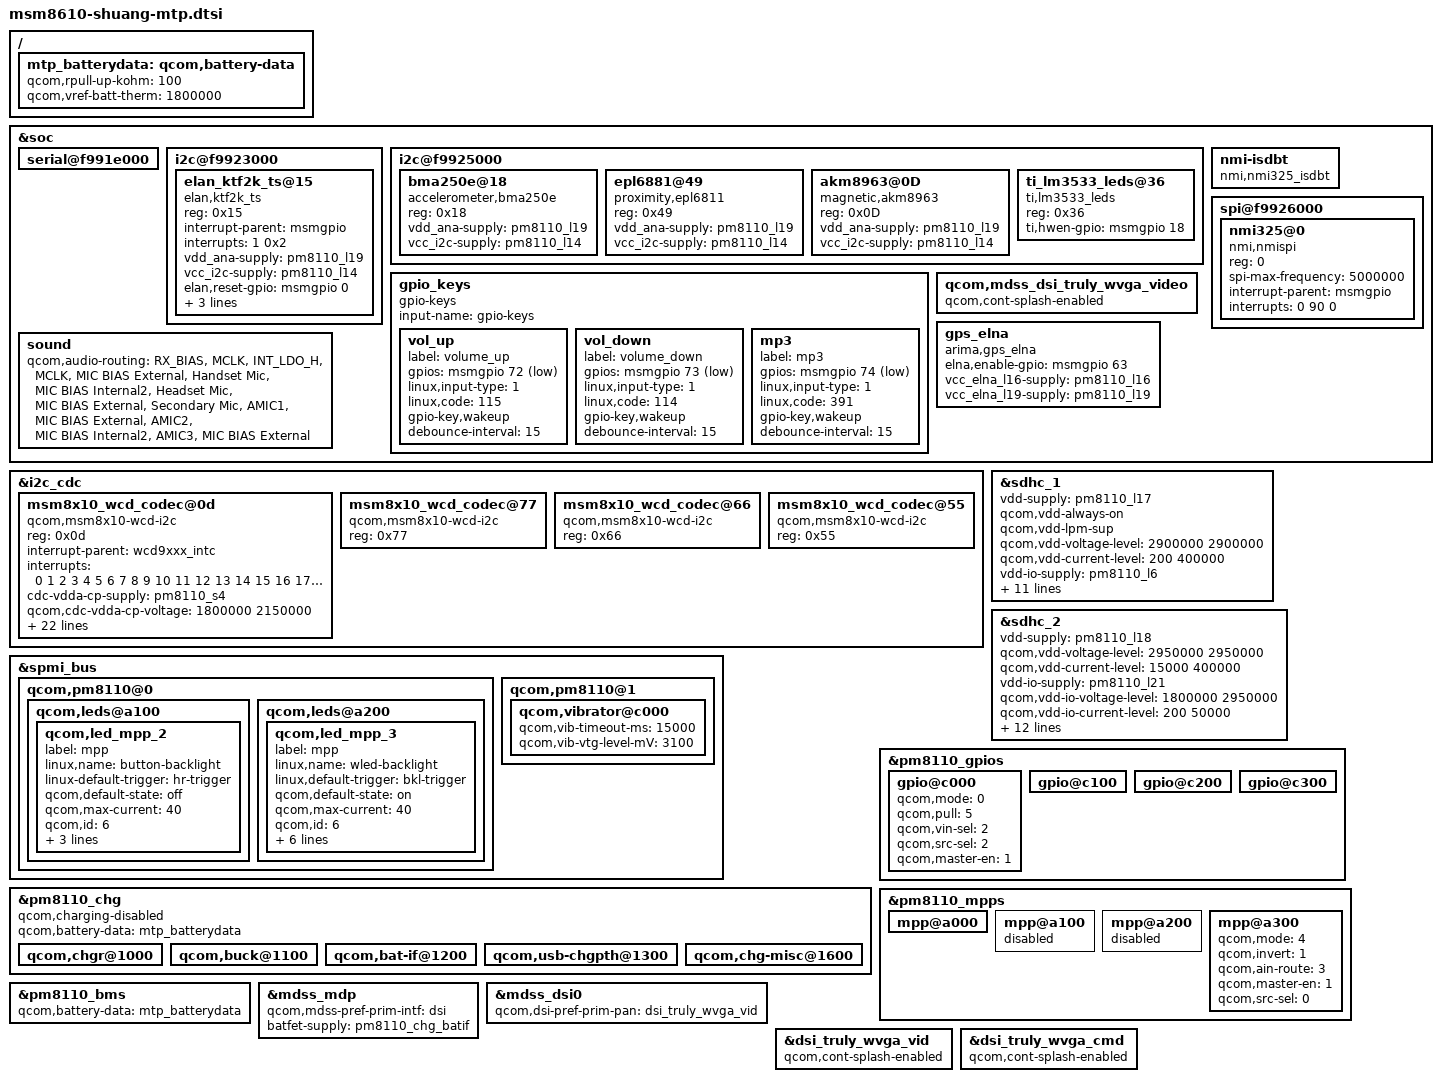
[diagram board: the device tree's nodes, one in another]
/* Copyright (c) 2013-2014, The Linux Foundation. All rights reserved.
 *
 * This program is free software; you can redistribute it and/or modify
 * it under the terms of the GNU General Public License version 2 and
 * only version 2 as published by the Free Software Foundation.
 *
 * This program is distributed in the hope that it will be useful,
 * but WITHOUT ANY WARRANTY; without even the implied warranty of
 * MERCHANTABILITY or FITNESS FOR A PARTICULAR PURPOSE.  See the
 * GNU General Public License for more details.
 */

&soc {
	serial@f991e000 {
		status = "ok";
	};

	i2c@f9923000 {
		elan_ktf2k_ts@15 {
			compatible = "elan,ktf2k_ts";
			reg = <0x15>;
			interrupt-parent = <&msmgpio>;
			interrupts = <1 0x2>;
			vdd_ana-supply = <&pm8110_l19>;
			vcc_i2c-supply = <&pm8110_l14>;
			elan,reset-gpio = <&msmgpio 0 0x00>;
			elan,irq-gpio = <&msmgpio 1 0x00>;
			elan,hw-det-gpio = <&msmgpio 7 0x00>;
			elan,i2c-pull-up;
		};
	};

	i2c@f9925000 {
		bma250e@18 {
			compatible = "accelerometer,bma250e";
			reg = <0x18>;
			vdd_ana-supply = <&pm8110_l19>;
			vcc_i2c-supply = <&pm8110_l14>;
		};
		epl6881@49 {
			compatible = "proximity,epl6811";
			reg = <0x49>;
			vdd_ana-supply = <&pm8110_l19>;
			vcc_i2c-supply = <&pm8110_l14>;
		};
		akm8963@0D {
			compatible = "magnetic,akm8963";
			reg = <0x0D>;
			vdd_ana-supply = <&pm8110_l19>;
			vcc_i2c-supply = <&pm8110_l14>;
		};
		ti_lm3533_leds@36 {
			compatible = "ti,lm3533_leds";
			reg = <0x36>;
			ti,hwen-gpio = <&msmgpio 18 0x00>;
		};
	};

	nmi-isdbt {
		compatible = "nmi,nmi325_isdbt";
	};

	spi@f9926000 {
		nmi325@0 {
			compatible = "nmi,nmispi";
			reg = <0>;
			spi-max-frequency = <5000000>;
			interrupt-parent = <&msmgpio>;
			interrupts = <0 90 0>;
		};
	};

	gpio_keys {
		compatible = "gpio-keys";
		input-name = "gpio-keys";

		vol_up {
			label = "volume_up";
			gpios = <&msmgpio 72 0x1>;
			linux,input-type = <1>;
			linux,code = <115>;
			gpio-key,wakeup;
			debounce-interval = <15>;
		};

		vol_down {
			label = "volume_down";
			gpios = <&msmgpio 73 0x1>;
			linux,input-type = <1>;
			linux,code = <114>;
			gpio-key,wakeup;
			debounce-interval = <15>;
		};

		mp3 {
			label = "mp3";
			gpios = <&msmgpio 74 0x1>;
			linux,input-type = <1>;
			linux,code = <391>;
			gpio-key,wakeup;
			debounce-interval = <15>;
		};
	};

    sound {
        qcom,audio-routing =
            "RX_BIAS", "MCLK",
            "INT_LDO_H", "MCLK",
            "MIC BIAS External", "Handset Mic",
            "MIC BIAS Internal2", "Headset Mic",
            "MIC BIAS External", "Secondary Mic",
            "AMIC1", "MIC BIAS External",
            "AMIC2", "MIC BIAS Internal2",
            "AMIC3", "MIC BIAS External";
    };

	qcom,mdss_dsi_truly_wvga_video {
		qcom,cont-splash-enabled;
	};

	gps_elna {
		compatible = "arima,gps_elna";
		elna,enable-gpio = <&msmgpio 63 0x00>;
		vcc_elna_l16-supply = <&pm8110_l16>;
		vcc_elna_l19-supply = <&pm8110_l19>;
	};
};

&i2c_cdc  {
	msm8x10_wcd_codec@0d{
		compatible = "qcom,msm8x10-wcd-i2c";
		reg = <0x0d>;

		interrupt-parent = <&wcd9xxx_intc>;
		interrupts = <0 1 2 3 4 5 6 7 8 9 10 11 12 13 14 15 16
			      17 18 19 20 21 22 23>;

		cdc-vdda-cp-supply = <&pm8110_s4>;
		qcom,cdc-vdda-cp-voltage = <1800000 2150000>;
		qcom,cdc-vdda-cp-current = <650000>;

		cdc-vdda-h-supply = <&pm8110_l6>;
		qcom,cdc-vdda-h-voltage = <1800000 1800000>;
		qcom,cdc-vdda-h-current = <25000>;

		cdc-vdd-px-supply = <&pm8110_l6>;
		qcom,cdc-vdd-px-voltage = <1800000 1800000>;
		qcom,cdc-vdd-px-current = <10000>;

		cdc-vdd-1p2v-supply = <&pm8110_l4>;
		qcom,cdc-vdd-1p2v-voltage = <1200000 1200000>;
		qcom,cdc-vdd-1p2v-current = <5000>;

		cdc-vdd-mic-bias-supply = <&pm8110_l20>;
		qcom,cdc-vdd-mic-bias-voltage = <3075000 3075000>;
		qcom,cdc-vdd-mic-bias-current = <25000>;

		qcom,cdc-micbias-ldoh-v = <0x3>;
		qcom,cdc-micbias-cfilt-sel = <0x0>;
		qcom,cdc-micbias-cfilt-mv = <2700>;
		qcom,cdc-mclk-clk-rate = <12288000>;

		qcom,cdc-static-supplies = "cdc-vdda-h",
					   "cdc-vdd-px",
					   "cdc-vdd-1p2v";

		qcom,cdc-on-demand-supplies = "cdc-vdda-cp",
					      "cdc-vdd-mic-bias";
		qcom,cdc-micbias1-ext-cap;
	};

	msm8x10_wcd_codec@77{
		compatible = "qcom,msm8x10-wcd-i2c";
		reg = <0x77>;
	};

	msm8x10_wcd_codec@66{
		compatible = "qcom,msm8x10-wcd-i2c";
		reg = <0x66>;
	};

	msm8x10_wcd_codec@55{
		compatible = "qcom,msm8x10-wcd-i2c";
		reg = <0x55>;
	};
};

&spmi_bus {
	qcom,pm8110@0 {
		qcom,leds@a100 {
			status = "okay";
			qcom,led_mpp_2 {
				label = "mpp";
				linux,name = "button-backlight";
				linux-default-trigger = "hr-trigger";
				qcom,default-state = "off";
				qcom,max-current = <40>;
				qcom,id = <6>;
				qcom,source-sel = <1>;
				qcom,mode-ctrl = <0x60>;
				qcom,mode = "manual";
			};
		};

		qcom,leds@a200 {
			status = "okay";
			qcom,led_mpp_3 {
				label = "mpp";
				linux,name = "wled-backlight";
				linux,default-trigger = "bkl-trigger";
				qcom,default-state = "on";
				qcom,max-current = <40>;
				qcom,id = <6>;
				qcom,source-sel = <8>;
				qcom,mode-ctrl = <0x10>;
				qcom,pwm-channel = <0>;
				qcom,pwm-us = <27>;
				qcom,vin-ctrl = <0x03>;
				qcom,mode = "pwm";
			};
		};
	};
};

&spmi_bus {
	qcom,pm8110@1 {
		qcom,vibrator@c000 {
			status = "okay";
			qcom,vib-timeout-ms = <15000>;
			qcom,vib-vtg-level-mV = <3100>;
		};
	};
};

&sdhc_1 {
	vdd-supply = <&pm8110_l17>;
	qcom,vdd-always-on;
	qcom,vdd-lpm-sup;
	qcom,vdd-voltage-level = <2900000 2900000>;
	qcom,vdd-current-level = <200 400000>;

	vdd-io-supply = <&pm8110_l6>;
	qcom,vdd-io-always-on;
	qcom,vdd-io-voltage-level = <1800000 1800000>;
	qcom,vdd-io-current-level = <200 60000>;

	qcom,pad-pull-on = <0x0 0x3 0x3>; /* no-pull, pull-up, pull-up */
	qcom,pad-pull-off = <0x0 0x3 0x3>; /* no-pull, pull-up, pull-up */
	qcom,pad-drv-on = <0x4 0x4 0x4>; /* 10mA, 10mA, 10mA */
	qcom,pad-drv-off = <0x0 0x0 0x0>; /* 2mA, 2mA, 2mA */

	qcom,clk-rates = <400000 25000000 50000000 100000000 200000000>;
	qcom,bus-speed-mode = "HS200_1p8v", "DDR_1p8v";
	qcom,nonremovable;

	status = "ok";
};

&sdhc_2 {
	vdd-supply = <&pm8110_l18>;
	qcom,vdd-voltage-level = <2950000 2950000>;
	qcom,vdd-current-level = <15000 400000>;

	vdd-io-supply = <&pm8110_l21>;
	qcom,vdd-io-voltage-level = <1800000 2950000>;
	qcom,vdd-io-current-level = <200 50000>;

	qcom,pad-pull-on = <0x0 0x3 0x3>; /* no-pull, pull-up, pull-up */
	qcom,pad-pull-off = <0x0 0x3 0x3>; /* no-pull, pull-up, pull-up */
	qcom,pad-drv-on = <0x4 0x4 0x4>; /* 10mA, 10mA, 10mA */
	qcom,pad-drv-off = <0x0 0x0 0x0>; /* 2mA, 2mA, 2mA */

	qcom,clk-rates = <400000 25000000 50000000 100000000 200000000>;

	#address-cells = <0>;
	interrupt-parent = <&sdhc_2>;
	interrupts = <0 1 2>;
	#interrupt-cells = <1>;
	interrupt-map-mask = <0xffffffff>;
	interrupt-map = <0 &intc 0 125 0
			1 &intc 0 221 0
			2 &msmgpio 42 0x3>;
	interrupt-names = "hc_irq", "pwr_irq", "status_irq";
	cd-gpios = <&msmgpio 42 0x1>;

	status = "ok";
};

&pm8110_chg {
	status = "ok";
	qcom,charging-disabled;

	qcom,chgr@1000 {
		status = "ok";
	};

	qcom,buck@1100 {
		status = "ok";
	};

	qcom,bat-if@1200 {
		status = "ok";
	};

	qcom,usb-chgpth@1300 {
		status = "ok";
	};

	qcom,chg-misc@1600 {
		status = "ok";
	};
};

&pm8110_gpios {
	gpio@c000 { /* GPIO 1 */
		qcom,mode = <0>;		/* QPNP_PIN_MODE_DIG_IN */
		qcom,pull = <5>;		/* QPNP_PIN_PULL_NO */
		qcom,vin-sel = <2>;		/* QPNP_PIN_VIN2 */
		qcom,src-sel = <2>;		/* QPNP_PIN_SEL_FUNC_1 */
		qcom,master-en = <1>;
	};

	gpio@c100 { /* GPIO 2 */
	};

	gpio@c200 { /* GPIO 3 */
	};

	gpio@c300 { /* GPIO 4 */
	};
};

&pm8110_mpps {
	mpp@a000 { /* MPP 1 */
	};

	mpp@a100 { /* MPP 2 */
		status = "disabled";
	};

	mpp@a200 { /* MPP 3 */
		status = "disabled";
	};

	mpp@a300 { /* MPP 4 */
		/* PA_THERM config */
		qcom,mode = <4>; /* AIN input */
		qcom,invert = <1>; /* Enable MPP */
		qcom,ain-route = <3>; /* AMUX 8 */
		qcom,master-en = <1>;
		qcom,src-sel = <0>; /* Function constant */
	};
};

/ {
	mtp_batterydata: qcom,battery-data {
		qcom,rpull-up-kohm = <100>;
		qcom,vref-batt-therm = <1800000>;

		/include/ "../batterydata-palladium.dtsi"
		/include/ "../batterydata-mtp-3000mah.dtsi"
	};
};

&pm8110_bms {
	status = "ok";
	qcom,battery-data = <&mtp_batterydata>;
};

&pm8110_chg {
	qcom,battery-data = <&mtp_batterydata>;
};

&mdss_mdp {
	qcom,mdss-pref-prim-intf = "dsi";
	batfet-supply = <&pm8110_chg_batif>;
};

&mdss_dsi0 {
	qcom,dsi-pref-prim-pan = <&dsi_truly_wvga_vid>;
};

&dsi_truly_wvga_vid {
	qcom,cont-splash-enabled;
};

&dsi_truly_wvga_cmd {
	qcom,cont-splash-enabled;
};
